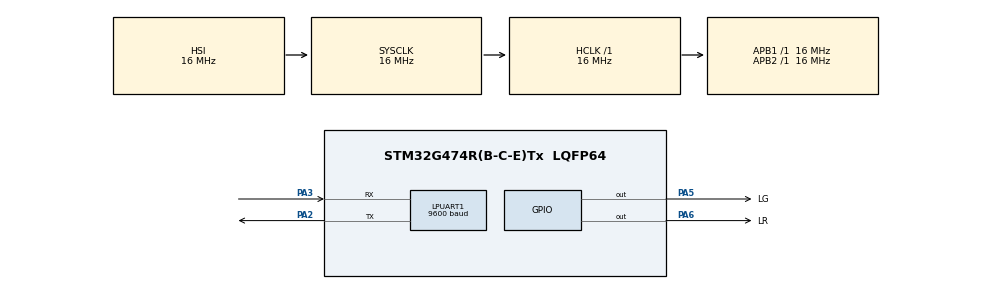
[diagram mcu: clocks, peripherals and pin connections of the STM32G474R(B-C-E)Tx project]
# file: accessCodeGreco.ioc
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Dma.LPUART1_TX.0.Direction=DMA_MEMORY_TO_PERIPH
Dma.LPUART1_TX.0.EventEnable=DISABLE
Dma.LPUART1_TX.0.Instance=DMA1_Channel1
Dma.LPUART1_TX.0.MemDataAlignment=DMA_MDATAALIGN_BYTE
Dma.LPUART1_TX.0.MemInc=DMA_MINC_ENABLE
Dma.LPUART1_TX.0.Mode=DMA_NORMAL
Dma.LPUART1_TX.0.PeriphDataAlignment=DMA_PDATAALIGN_BYTE
Dma.LPUART1_TX.0.PeriphInc=DMA_PINC_DISABLE
Dma.LPUART1_TX.0.Polarity=HAL_DMAMUX_REQ_GEN_RISING
Dma.LPUART1_TX.0.Priority=DMA_PRIORITY_LOW
Dma.LPUART1_TX.0.RequestNumber=1
Dma.LPUART1_TX.0.SignalID=NONE
Dma.LPUART1_TX.0.SyncEnable=DISABLE
Dma.LPUART1_TX.0.SyncPolarity=HAL_DMAMUX_SYNC_NO_EVENT
Dma.LPUART1_TX.0.SyncRequestNumber=1
Dma.LPUART1_TX.0.SyncSignalID=NONE
Dma.Request0=LPUART1_TX
LPUART1.BaudRate=9600
Mcu.Family=STM32G4
Mcu.Name=STM32G474R(B-C-E)Tx
Mcu.Package=LQFP64
NVIC.DMA1_Channel1_IRQn=true\:0\:0\:false\:false\:true\:false\:true\:true
NVIC.LPUART1_IRQn=true\:0\:0\:false\:false\:true\:true\:true\:true
NVIC.PriorityGroup=NVIC_PRIORITYGROUP_4
NVIC.TIM6_DAC_IRQn=true\:0\:0\:false\:false\:true\:true\:true\:true
PA2.Mode=Asynchronous
PA2.Signal=LPUART1_TX
PA3.Mode=Asynchronous
PA3.Signal=LPUART1_RX
PA5.GPIO_Label=LG
PA5.Signal=GPIO_Output
PA6.GPIO_Label=LR
PA6.Signal=GPIO_Output
ProjectManager.HeapSize=0x200
ProjectManager.StackSize=0x400
ProjectManager.TargetToolchain=STM32CubeIDE
RCC.AHBFreq_Value=16000000
RCC.APB1Freq_Value=16000000
RCC.APB1TimFreq_Value=16000000
RCC.APB2Freq_Value=16000000
RCC.APB2TimFreq_Value=16000000
RCC.CortexFreq_Value=16000000
RCC.EXTERNAL_CLOCK_VALUE=12288000
RCC.HCLKFreq_Value=16000000
RCC.HSE_VALUE=8000000
RCC.HSI48_VALUE=48000000
RCC.HSI_VALUE=16000000
RCC.LSE_VALUE=32768
RCC.SYSCLKFreq_VALUE=16000000
RCC.USBFreq_Value=64000000
RCC.VCOOutputFreq_Value=128000000
VP_SYS_VS_DBSignals.Mode=DisableDeadBatterySignals
VP_TIM6_VS_ClockSourceINT.Mode=Enable_Timer
board=custom

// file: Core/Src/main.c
/* USER CODE BEGIN Header */
/**
  ******************************************************************************
  * @file           : main.c
  * @brief          : Main program body
  ******************************************************************************
  * @attention
  *
  * Copyright (c) 2026 STMicroelectronics.
  * All rights reserved.
  *
  * This software is licensed under terms that can be found in the LICENSE file
  * in the root directory of this software component.
  * If no LICENSE file comes with this software, it is provided AS-IS.
  *
  ******************************************************************************
  */
/* USER CODE END Header */
#include "main.h"
#include "dma.h"
#include "usart.h"
#include "tim.h"
#include "gpio.h"
#include "fsm_logic.h"

void SystemClock_Config(void);

int main(void)
{

  /* MCU Configuration--------------------------------------------------------*/

  /* Reset of all peripherals, Initializes the Flash interface and the Systick. */
  HAL_Init();

  /* Configure the system clock */
  SystemClock_Config();

  /* Initialize all configured peripherals */
  MX_GPIO_Init();
  MX_DMA_Init();
  MX_LPUART1_UART_Init();
  MX_TIM6_Init();

  led_t lg , lr;
  timer_t timer;
  uint32_t cycle = 40;

 if(led_init(&lg ,LG_GPIO_Port , LG_Pin , GPIO_PIN_RESET) != LED_OK) return -1;
 if(led_init(&lr , LR_GPIO_Port , LR_Pin , GPIO_PIN_RESET) != LED_OK) return -1;
 if(timer_init(&timer , &htim6 , 16000000) != TIMER_OK) return -1;
 /* USER CODE BEGIN 2 */
   led_on(&lg);
   HAL_Delay(1000);
   led_off(&lg);

 if(FSM_init(cycle , &lg , &lr , &timer)!=FSM_OK) return -1;
  /* USER CODE END 2 */

  /* Infinite loop */
  /* USER CODE BEGIN WHILE */
  while (1)
  {
	  if(FSM_step() != FSM_OK) return -1;
    /* USER CODE END WHILE */

  }
}

void SystemClock_Config(void)
{
  RCC_OscInitTypeDef RCC_OscInitStruct = {0};
  RCC_ClkInitTypeDef RCC_ClkInitStruct = {0};

  /** Configure the main internal regulator output voltage
  */
  HAL_PWREx_ControlVoltageScaling(PWR_REGULATOR_VOLTAGE_SCALE1);

  /** Initializes the RCC Oscillators according to the specified parameters
  * in the RCC_OscInitTypeDef structure.
  */
  RCC_OscInitStruct.OscillatorType = RCC_OSCILLATORTYPE_HSI;
  RCC_OscInitStruct.HSIState = RCC_HSI_ON;
  RCC_OscInitStruct.HSICalibrationValue = RCC_HSICALIBRATION_DEFAULT;
  RCC_OscInitStruct.PLL.PLLState = RCC_PLL_NONE;
  if (HAL_RCC_OscConfig(&RCC_OscInitStruct) != HAL_OK)
  {
    Error_Handler();
  }

  /** Initializes the CPU, AHB and APB buses clocks
  */
  RCC_ClkInitStruct.ClockType = RCC_CLOCKTYPE_HCLK|RCC_CLOCKTYPE_SYSCLK
                              |RCC_CLOCKTYPE_PCLK1|RCC_CLOCKTYPE_PCLK2;
  RCC_ClkInitStruct.SYSCLKSource = RCC_SYSCLKSOURCE_HSI;
  RCC_ClkInitStruct.AHBCLKDivider = RCC_SYSCLK_DIV1;
  RCC_ClkInitStruct.APB1CLKDivider = RCC_HCLK_DIV1;
  RCC_ClkInitStruct.APB2CLKDivider = RCC_HCLK_DIV1;

  if (HAL_RCC_ClockConfig(&RCC_ClkInitStruct, FLASH_LATENCY_0) != HAL_OK)
  {
    Error_Handler();
  }
}

void Error_Handler(void)
{
  __disable_irq();
  while (1)
  {
  }
}
